# NAME register map
Vendor: XXX; Series: SP; File version: 1.2
ARM 32-bit Cortex-M3 Microcontroller based device, CPU clock up to 80MHz, etc.
CPU: CM3 r1p0, little endian, MPU, FPU, 3 interrupt priority bits
Registers are 32-bit, read-write, reset 0x0 unless marked. A register's access mark holds for its fields unless they carry their own. Offsets are from the block's base; lines under a group give offsets from that group; [hi:lo] are bit positions; {n}, {i} and the like mark numbered series; 'fields as' and 'values as' point back to an identical list; <NAME> marks a mode.

## Memory map
0x40010000 TIMER0 size 0x100 — 32 Timer / Counter, counting up or down from different sources

## Interrupts
0 TIMER0

## TIMER0 — 32 Timer / Counter, counting up or down from different sources
Base 0x40010000
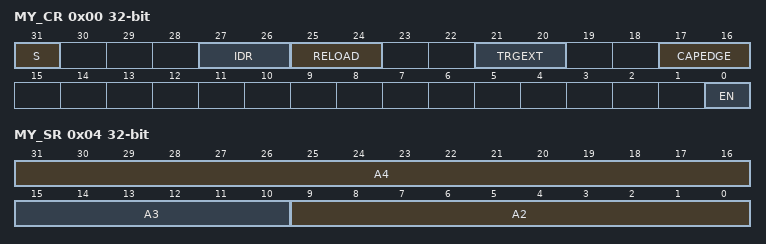
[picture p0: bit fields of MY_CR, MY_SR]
0x00 MY_CR (reset mask 0x1337F7F) — Test 1
  [31] S ro — Starts and Stops the Timer / Counter
  [27:26] IDR ro — Selects, if Reload Register number is incremented, decremented or not modified
  [25:24] RELOAD ro — Select RELOAD Register n to reload Timer on condition
  [21:20] TRGEXT — Triggers an other Peripheral
  [17:16] CAPEDGE — Capture Edge, select which Edge should result in a counter increment or decrement
  [0] EN — Enable
0x04 MY_SR — Test 2
  [31:16] A4 ro — test a4
  [15:10] A3 — test a3
  [9:0] A2 ro — test a2
0x08 reload — Test 3 - to reload
